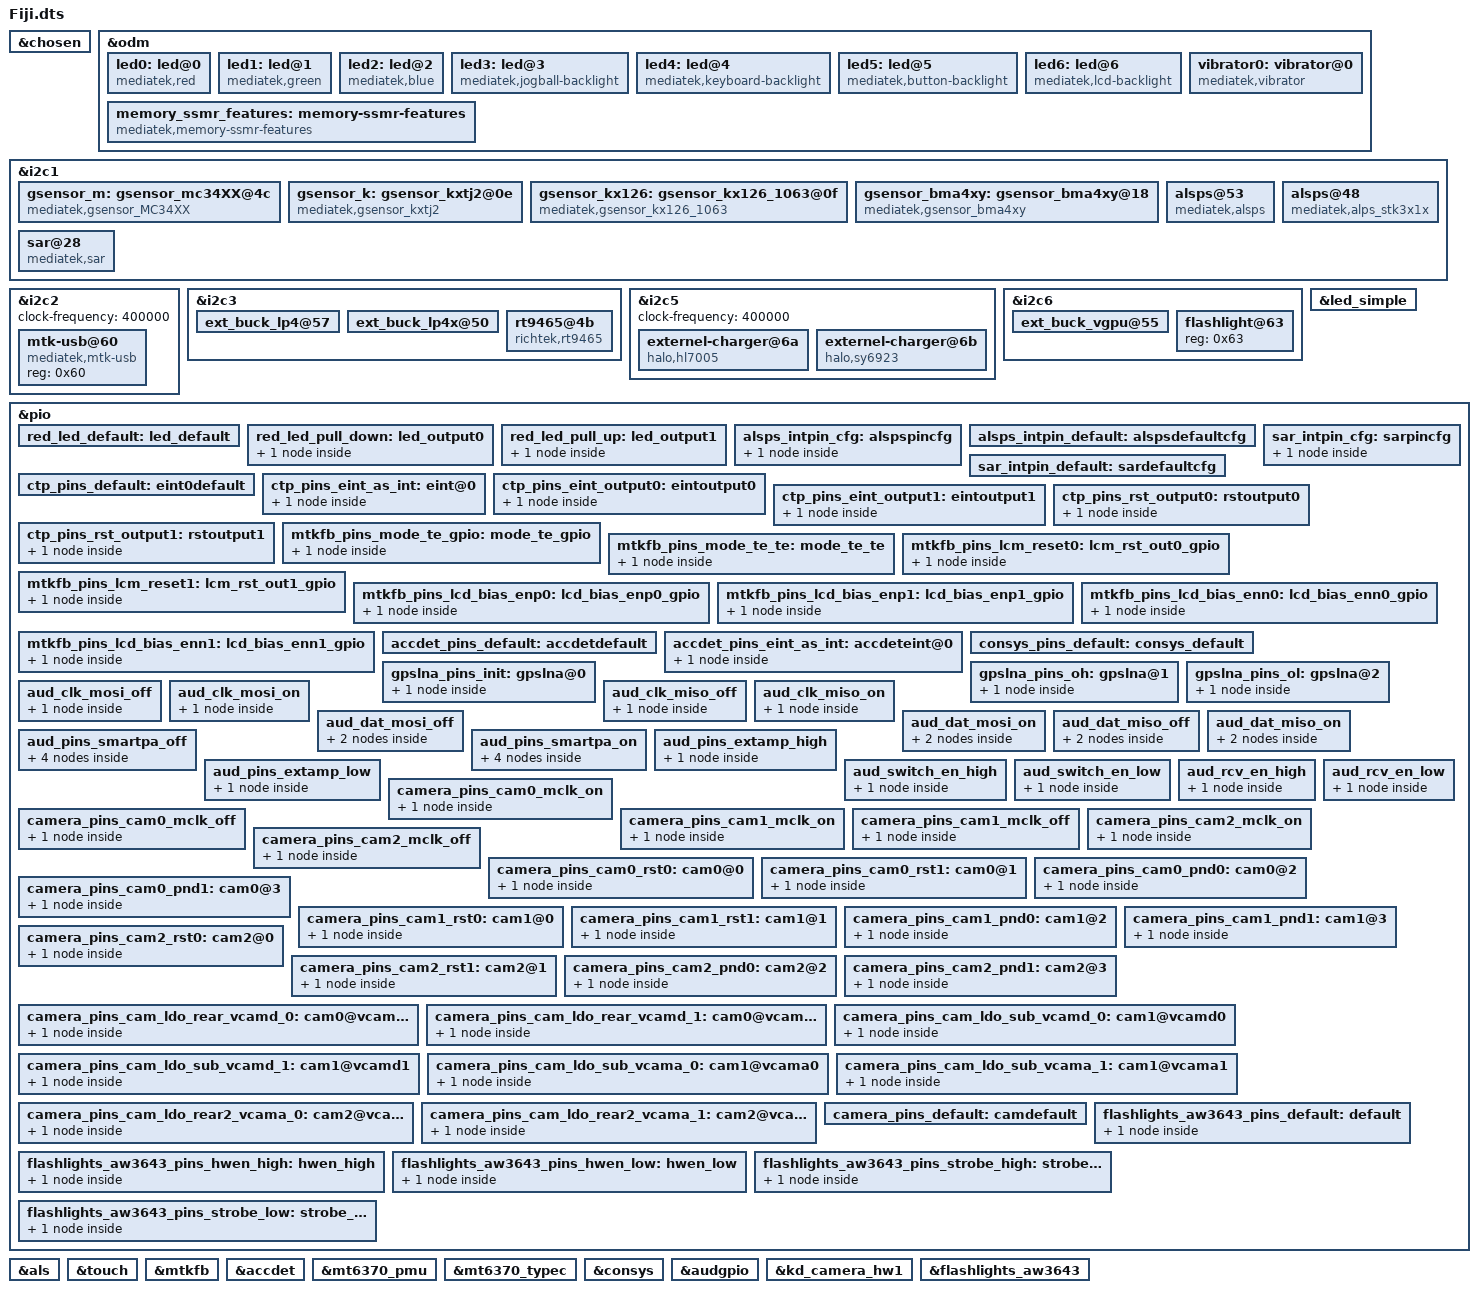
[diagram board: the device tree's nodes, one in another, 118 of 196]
#include <dt-bindings/interrupt-controller/arm-gic.h>
#include <dt-bindings/interrupt-controller/irq.h>
#include <dt-bindings/pinctrl/mt6761-pinfunc.h>
#include <dt-bindings/mmc/mt6761-msdc.h>
#include <dt-bindings/clock/mt6761-clk.h>

/dts-v1/;
/plugin/;

/* chosen */
&chosen {

	/* fpga may has no lk, we need to specify display info here */
	/* fb buffer is reserved using this dts by memory node above */
	atag,videolfb-fb_base_h = <0x0>;
	atag,videolfb-fb_base_l = <0x5e605000>;
	atag,videolfb-islcmfound = <1>;
	/* because no lk, so lcm is not inited */
	atag,videolfb-islcm_inited = <0>;
	atag,videolfb-fps= <6000>;
	atag,videolfb-vramSize= <0x017bb000>;
	atag,videolfb-lcmname= "nt35521_hd_dsi_vdo_truly_rt5081_drv";
};

&odm {
	led0:led@0 {
		compatible = "mediatek,red";
		led_mode = <3>;
		data = <1>;
		pwm_config = <0 0 0 0 0>;
	};
	led1:led@1 {
		compatible = "mediatek,green";
		led_mode = <3>;
		data = <2>;
		pwm_config = <0 0 0 0 0>;
	};
	led2:led@2 {
		compatible = "mediatek,blue";
		led_mode = <0>;
		data = <1>;
		pwm_config = <0 0 0 0 0>;
	};
	led3:led@3 {
		compatible = "mediatek,jogball-backlight";
		led_mode = <0>;
		data = <1>;
		pwm_config = <0 0 0 0 0>;
	};
	led4:led@4 {
		compatible = "mediatek,keyboard-backlight";
		led_mode = <0>;
		data = <1>;
		pwm_config = <0 0 0 0 0>;
	};
	led5:led@5 {
		compatible = "mediatek,button-backlight";
		led_mode = <0>;
		data = <1>;
		pwm_config = <0 0 0 0 0>;
	};
	led6:led@6 {
		compatible = "mediatek,lcd-backlight";
		led_mode = <4>;
		data = <1>;
		pwm_config = <0 2 0 0 0>;
	};
	vibrator0:vibrator@0 {
		compatible = "mediatek,vibrator";
		vib_timer = <25>;
		vib_limit = <9>;
		vib_vol= <0x0b>;
	};
	memory_ssmr_features: memory-ssmr-features {
		compatible = "mediatek,memory-ssmr-features";
		svp-size = <0 0>;
		iris-recognition-size = <0 0>;
		2d_fr-size = <0 0>;
		tui-size = <0 0>;
		wfd-size = <0 0>;
		prot-sharedmem-size = <0 0>;
	};
};

&i2c1 {
/*  start sensor */
	/*
	memsic@0 {
		compatible = “mediatek,mmc5603”;
		i2c_num = <1>;
		i2c_addr = <0x30 0 0 0>; 
		direction - <1>;
		is_batch_supported = <0>;
	}
	*/
	gsensor_m:gsensor_mc34XX@4c {
		compatible = "mediatek,gsensor_MC34XX";
		reg = <0x4c>;
		status = "okay";

		i2c_num	= <1>;
		i2c_addr = <0x4c 0 0 0>;
		direction = <2>;
		power_id = <0xffff>;
		power_vol = <0>;
		firlen = <16>;
		is_batch_supported = <1>;
	};

  	gsensor_k:gsensor_kxtj2@0e {
		compatible = "mediatek,gsensor_kxtj2";
		reg = <0x0e>;
		status = "okay";
		
		i2c_num	= <1>;
		i2c_addr = <0x0e 0 0 0>;
		direction = <6>;
		power_id = <0xffff>;
		power_vol = <0>;
		firlen = <16>;
		is_batch_supported = <1>;
	};
	gsensor_kx126:gsensor_kx126_1063@0f {
		compatible = "mediatek,gsensor_kx126_1063";
		reg = <0x0f>;
		status = "okay";
		
		i2c_num	= <1>;
		i2c_addr = <0x0f 0 0 0>;
		direction = <6>;
		power_id = <0xffff>;
		power_vol = <0>;
		firlen = <16>;
		is_batch_supported = <1>;
	};
	gsensor_bma4xy:gsensor_bma4xy@18 {
		compatible = "mediatek,gsensor_bma4xy";
		reg = <0x18>;
		status = "okay";
		
		i2c_num	= <1>;
		i2c_addr = <0x18 0 0 0>;
		direction = <6>;
		power_id = <0xffff>;
		power_vol = <0>;
		firlen = <16>;
		is_batch_supported = <1>;
	}; 

	alsps@53 {
		compatible = "mediatek,alsps";

		pinctrl-names = "pin_default", "pin_cfg";
		pinctrl-0 = <&alsps_intpin_default>;
		pinctrl-1 = <&alsps_intpin_cfg>;

		i2c_num = <1>;
		i2c_addr= <0x53 0 0 0>;
		polling_mode_ps = <0>;
		polling_mode_als = <1>;
		power_id = <0xffff>;
		power_vol = <0>;
		als_level = <
			0  133  304  502   1004  2005  3058 4000
			0  133  304   502  1004  2005  3058 4000
			0  133  304   502  1004  2005  3058 4000
			0  133  304  502   1004  2005  3058 4000
			0  133  304   502  1004  2005  3058 4000
			0  133  304   502  1004  2005  3058 4000
			>;
		als_value = < 0  133  304  502   1004  2005  3058   4000 >;
		ps_threshold_high               =  <700>;
		ps_threshold_low                =  <600>;
		is_batch_supported_ps = <0>;
		is_batch_supported_als = <0>;

	};

	alsps@48 {
		compatible = "mediatek,alps_stk3x1x";
		reg = <0x48>;
		status = "okay";

		pinctrl-names = "pin_default", "pin_cfg";
		pinctrl-0 = <&alsps_intpin_default>;
		pinctrl-1 = <&alsps_intpin_cfg>;

		interrupt-parent = <&pio>;
		interrupts = <1 IRQ_TYPE_LEVEL_LOW 1 0>;

		i2c_num				= <1>;
		i2c_addr				= <0x48 0 0 0>;
		polling_mode_ps			= <0>;
		polling_mode_als		= <1>;
		power_id				= <0xffff>;
		power_vol				= <0>;
		als_level = < 
					0  39   91    150    290    505     736    943
					0  82   174   299    582    1319    2940  3333
					0  123   264   399    627    1444   2144   2800
					0  63   144    237    445    724     991    1231
					0  72   163   258    560    1576   2400   3152
					0  112   240   475    746    1719   2552   3333
					  >;
		als_value = < 0  133  304  502   1004  2005  3058   4000 >;
		state_val		=  <0>;
		psctrl_val		=  <0x31>;
		alsctrl_val	= <0x38>;
		ledctrl_val	= <0xFF>;
		wait_val		= <0xF>;
		ps_threshold_high		=  <1700>;
		ps_threshold_low		=  <1500>;
		is_batch_supported_ps	= <0>;
		is_batch_supported_als	= <0>;
		//
                als_calib_enable = <1>;
                als_ch0_expect               =  <1000>;
                als_ch1_expect                =  <800>;
               // 
	};  

	sar@28 {
		compatible = "mediatek,sar";
		reg = <0x28>;

		pinctrl-names = "pin_default", "pin_cfg";
        pinctrl-0 = <&sar_intpin_default>;
        pinctrl-1 = <&sar_intpin_cfg>;

		Semtech,reg-num = <46>; /* total registers number to initialize*/
        Semtech,reg-init  = /bits/ 8 < 0x10 0x16
                                0x20 0x00
                                0x23 0x00
                                0x24 0x44
                                0x26 0x01
                                0x27 0x44
                                0x28 0x01 /*PH0 to CS0 input*/
                                0x29 0x10
                                0x2A 0x19 /*PH2 CS2-input,CS1-dync,CS0-HZ*/
                                0x2B 0x00
                                0x2C 0x12
                                0x2D 0x08
                                0x30 0x09
                                0x31 0x09
                                0x32 0x08
                                0x33 0x20
                                0x34 0x0C
                                0x35 0x00
                                0x36 0x1B
                                0x37 0x1B
                                0x40 0x00
                                0x41 0x00
                                0x42 0x00
                                0x43 0x00
                                0x44 0x00
                                0x45 0x05
                                0x46 0x00
                                0x47 0x00
                                0x48 0x00
                                0x49 0x80
                                0x4A 0x00
                                0x4B 0x00
                                0x4C 0x00
                                0x4D 0x00
                                0x4E 0x80
                                0x4F 0x0C
                                0x50 0x00
                                0x51 0x70
                                0x52 0x20
                                0x53 0xE1
                                0x54 0xF0
                                0x05 0x70
                                0x06 0x00
                                0x07 0x00
                                0x08 0x00
								0x11 0x24>;

	};

/* end sensor */
};
&i2c2 {
	#address-cells = <1>;
	#size-cells = <0>;
	clock-frequency = <400000>;

	mtk-usb@60 {
		compatible = "mediatek,mtk-usb";
		reg = <0x60>;
		status = "okay";
	};
};

&i2c3 {
	ext_buck_lp4@57 {
		regulator-name ="ext_buck_vdd2";
		regulator-min-microvolt = <300000>;
		regulator-max-microvolt = <1300000>;
		vsel_pin = <0>;
	};

	ext_buck_lp4x@50 {
		regulator-name ="ext_buck_vddq";
		regulator-min-microvolt = <300000>;
		regulator-max-microvolt = <1300000>;
		vsel_pin = <1>;
	};
};
&i2c5 {
	#address-cells = <1>;
	#size-cells = <0>;
	clock-frequency = <400000>;

	externel-charger@6a{
		compatible = "halo,hl7005";
		reg = <0x6a>;
		status = "okay";
		ichg = <1050000>; /* uA */
	};
	externel-charger@6b{
		compatible = "halo,sy6923";
		reg = <0x6b>;
		status = "okay";
		ichg = <1050000>; /* uA */
	};
};
&i2c6 {
	ext_buck_vgpu@55 {
		regulator-name ="ext_buck_vgpu";
		regulator-min-microvolt = <300000>;
		regulator-max-microvolt = <1300000>;
		vsel_pin = <2>;
	};
	flashlight@63 {
		reg = <0x63>;
		status = "okay";
	};
};
&led_simple {
	pinctrl-names = "default", "red_led_output0", "red_led_output1";
	pinctrl-0 = <&red_led_default>;
	pinctrl-1 = <&red_led_pull_down>;
	pinctrl-2 = <&red_led_pull_up>;
	status = "okay";
};
&pio {
	red_led_default: led_default {
	};
	red_led_pull_down: led_output0 {
		pins_cmd_dat {
			pinmux = <PINMUX_GPIO159__FUNC_GPIO159>;
			slew-rate = <1>;
			output-low;
		};
	};
	red_led_pull_up: led_output1 {
		pins_cmd_dat {
			pinmux = <PINMUX_GPIO159__FUNC_GPIO159>;
			slew-rate = <1>;
			output-high;
		};
	};
};

&als {
		pinctrl-names = "pin_default", "pin_cfg";
		pinctrl-0 = <&alsps_intpin_default>;
		pinctrl-1 = <&alsps_intpin_cfg>;
};

&pio {
	alsps_intpin_cfg: alspspincfg {

		pins_cmd_dat {
			pinmux = <PINMUX_GPIO6__FUNC_GPIO6>;
			slew-rate = <0>;
			bias-pull-up = <MTK_PUPD_SET_R1R0_01>;
		};
	};

	alsps_intpin_default: alspsdefaultcfg {

	};
};

&pio {
	sar_intpin_cfg: sarpincfg {

		pins_cmd_dat {
			pins = <PINMUX_GPIO2__FUNC_GPIO2>;
			slew-rate = <0>;
			bias-pull-up = <MTK_PUPD_SET_R1R0_01>;
		};
	};

	sar_intpin_default: sardefaultcfg {

	};
};

/* TOUCH start */
&touch {
	tpd-resolution = <720 1280>;
	use-tpd-button = <0>;
	tpd-key-num = <3>;
	tpd-key-local= <139 172 158 0>;
	tpd-key-dim-local = <90 883 100 40 230
				 883 100 40 370 883 100 40 0 0 0 0>;
	tpd-max-touch-num = <5>;
	tpd-filter-enable = <1>;
	tpd-filter-pixel-density = <106>;
	tpd-filter-custom-prameters = <0 0 0 0 0 0 0 0 0 0 0 0>;
	tpd-filter-custom-speed = <0 0 0>;
	pinctrl-names = "default", "state_eint_as_int", "state_eint_output0",
		"state_eint_output1", "state_rst_output0", "state_rst_output1";
	pinctrl-0 = <&ctp_pins_default>;
	pinctrl-1 = <&ctp_pins_eint_as_int>;
	pinctrl-2 = <&ctp_pins_eint_output0>;
	pinctrl-3 = <&ctp_pins_eint_output1>;
	pinctrl-4 = <&ctp_pins_rst_output0>;
	pinctrl-5 = <&ctp_pins_rst_output1>;
	status = "okay";
};
&pio {
	ctp_pins_default: eint0default {
	};
	ctp_pins_eint_as_int: eint@0 {
		pins_cmd_dat {
			pinmux = <PINMUX_GPIO0__FUNC_GPIO0>;
			slew-rate = <0>;
			bias-disable;
		};
	};
	ctp_pins_eint_output0: eintoutput0 {
		pins_cmd_dat {
			pinmux = <PINMUX_GPIO0__FUNC_GPIO0>;
			slew-rate = <1>;
			output-low;
		};
	};
	ctp_pins_eint_output1: eintoutput1 {
		pins_cmd_dat {
			pinmux = <PINMUX_GPIO0__FUNC_GPIO0>;
			slew-rate = <1>;
			output-high;
		};
	};
	ctp_pins_rst_output0: rstoutput0 {
		pins_cmd_dat {
			pinmux = <PINMUX_GPIO174__FUNC_GPIO174>;
			slew-rate = <1>;
			output-low;
		};
	};
	ctp_pins_rst_output1: rstoutput1 {
		pins_cmd_dat {
			pinmux = <PINMUX_GPIO174__FUNC_GPIO174>;
			slew-rate = <1>;
			output-high;
		};
	};
};
/* TOUCH end */
/* DISPSYS GPIO standardization */
&pio {
	mtkfb_pins_mode_te_gpio: mode_te_gpio {
		pins_cmd_dat {
			pinmux = <PINMUX_GPIO44__FUNC_DSI_TE>;
		};
	};

	mtkfb_pins_mode_te_te: mode_te_te {
		pins_cmd_dat {
			pinmux = <PINMUX_GPIO44__FUNC_DSI_TE>;
		};
	};

	mtkfb_pins_lcm_reset0: lcm_rst_out0_gpio {
		pins_cmd_dat {
			pinmux = <PINMUX_GPIO45__FUNC_GPIO45>;
			slew-rate = <1>;
			output-low;
		};
	};

	mtkfb_pins_lcm_reset1: lcm_rst_out1_gpio {
		pins_cmd_dat {
			pinmux = <PINMUX_GPIO45__FUNC_GPIO45>;
			slew-rate = <1>;
			output-high;
		};
	};

	mtkfb_pins_lcd_bias_enp0: lcd_bias_enp0_gpio {
		pins_cmd_dat {
			pinmux = <PINMUX_GPIO172__FUNC_GPIO172>;
			slew-rate = <1>;
			output-low;
		};
	};
	mtkfb_pins_lcd_bias_enp1: lcd_bias_enp1_gpio {
		pins_cmd_dat {
			pinmux = <PINMUX_GPIO172__FUNC_GPIO172>;
			slew-rate = <1>;
			output-high;
		};
	};

	mtkfb_pins_lcd_bias_enn0: lcd_bias_enn0_gpio {
		pins_cmd_dat {
			pinmux = <PINMUX_GPIO173__FUNC_GPIO173>;
			slew-rate = <1>;
			output-low;
		};
	};
	mtkfb_pins_lcd_bias_enn1: lcd_bias_enn1_gpio {
		pins_cmd_dat {
			pinmux = <PINMUX_GPIO173__FUNC_GPIO173>;
			slew-rate = <1>;
			output-high;
		};
	};

};

&mtkfb {
	pinctrl-names = "mode_te_gpio", "mode_te_te", "lcm_rst_out0_gpio",
		"lcm_rst_out1_gpio","lcd_bias_enp0_gpio", "lcd_bias_enp1_gpio", "lcd_bias_enn0_gpio", "lcd_bias_enn1_gpio";
	pinctrl-0 = <&mtkfb_pins_mode_te_gpio>;
	pinctrl-1 = <&mtkfb_pins_mode_te_te>;
	pinctrl-3 = <&mtkfb_pins_lcm_reset0>;
	pinctrl-4 = <&mtkfb_pins_lcm_reset1>;
	pinctrl-7 = <&mtkfb_pins_lcd_bias_enp0>;
	pinctrl-8 = <&mtkfb_pins_lcd_bias_enp1>;
	pinctrl-9 = <&mtkfb_pins_lcd_bias_enn0>;
	pinctrl-10 = <&mtkfb_pins_lcd_bias_enn1>;
	status = "okay";
};
/* DISPSYS GPIO standardization end */
&accdet {
	accdet-mic-vol = <6>;
	headset-mode-setting = <0x500 0x500 1 0x1f0 0x800 0x800 0x20 0x44>;
	accdet-plugout-debounce = <1>;
	accdet-mic-mode = <1>;
	headset-eint-level-pol = <8>;
	headset-three-key-threshold = <0 80 175 400>;
	headset-three-key-threshold-CDD = <0 121 192 600>;
	headset-four-key-threshold = <0 58 121 192 400>;
	pinctrl-names = "default", "state_eint_as_int";
	pinctrl-0 = <&accdet_pins_default>;
	pinctrl-1 = <&accdet_pins_eint_as_int>;
	status = "okay";
};
&pio {
	accdet_pins_default: accdetdefault {
	};
	accdet_pins_eint_as_int: accdeteint@0 {
		pins_cmd_dat {
			pinmux = <PINMUX_GPIO9__FUNC_GPIO9>;
			slew-rate = <0>;
			bias-disable;
		};
	};
};

&mt6370_pmu {
	mt6370,intr_gpio_num = <11>; /* direct defined GPIO num */
	mt6370,intr_gpio = <&pio 11 0x0>;
};
#if 0
&charger {
	algorithm_name = "DualSwitchCharging";
	chg1_ta_ac_charger_current = <2000000>;
	chg2_ta_ac_charger_current = <2000000>;
};
#endif
&i2c3 {
	rt9465@4b {
		compatible = "richtek,rt9465";
		reg = <0x4b>;
		status = "okay";
		rt,en_gpio_num = <176>;
		rt,en_gpio = <&pio 176 0x0>;
		rt,intr_gpio_num = <23>; /* direct defined GPIO num */
		rt,intr_gpio = <&pio 23 0x0>;
		interrupt-names = "wdtmri";
		charger_name = "secondary_chg";
		ichg = <1500000>; /* uA */
		mivr = <4500000>; /* uV */
		cv = <4550000>; /* uV */
		ieoc = <700000>; /* uA */
		safety_timer = <12>; /* hour */
		en_st; /* safety timer */
		/* en_te; */
		en_wdt;
	};
};

&mt6370_typec {
	mt6370pd,intr_gpio_num = <41>; /* direct defined GPIO num */
	mt6370pd,intr_gpio = <&pio 41 0x0>;
};
/* CONSYS GPIO standardization */
&pio {
	consys_pins_default: consys_default {
	};
	gpslna_pins_init: gpslna@0 {
		pins_cmd_dat {
			pinmux = <PINMUX_GPIO91__FUNC_GPIO91>;
			slew-rate = <0>;
			bias-disable;
			output-low;
		};
	};
	gpslna_pins_oh: gpslna@1 {
		pins_cmd_dat {
			pinmux = <PINMUX_GPIO91__FUNC_GPIO91>;
			slew-rate = <1>;
			output-high;
		};
	};
	gpslna_pins_ol: gpslna@2 {
		pins_cmd_dat {
			pinmux = <PINMUX_GPIO91__FUNC_GPIO91>;
			slew-rate = <1>;
			output-low;
		};
	};
};
&consys {
	pinctrl-names = "default", "gps_lna_state_init",
		"gps_lna_state_oh", "gps_lna_state_ol";
	pinctrl-0 = <&consys_pins_default>;
	pinctrl-1 = <&gpslna_pins_init>;
	pinctrl-2 = <&gpslna_pins_oh>;
	pinctrl-3 = <&gpslna_pins_ol>;
	status = "okay";
};
/* CONSYS end */

/* AUDIO GPIO standardization */
&audgpio {
	pinctrl-names = "aud_clk_mosi_off",
			"aud_clk_mosi_on",
			"aud_clk_miso_off",
			"aud_clk_miso_on",
			"aud_dat_mosi_off",
			"aud_dat_mosi_on",
			"aud_dat_miso_off",
			"aud_dat_miso_on",
			"aud_smartpa_off",
			"aud_smartpa_on",
			"extamp-pullhigh",
			"extamp-pulllow",
			"aud_switch_en_high",
			"aud_switch_en_low",
			"aud_rcv_en_high",
			"aud_rcv_en_low";
	pinctrl-0 = <&aud_clk_mosi_off>;
	pinctrl-1 = <&aud_clk_mosi_on>;
	pinctrl-2 = <&aud_clk_miso_off>;
	pinctrl-3 = <&aud_clk_miso_on>;
	pinctrl-4 = <&aud_dat_mosi_off>;
	pinctrl-5 = <&aud_dat_mosi_on>;
	pinctrl-6 = <&aud_dat_miso_off>;
	pinctrl-7 = <&aud_dat_miso_on>;
	pinctrl-8 = <&aud_pins_smartpa_off>;
	pinctrl-9 = <&aud_pins_smartpa_on>;
	pinctrl-10 = <&aud_pins_extamp_high>;
	pinctrl-11 = <&aud_pins_extamp_low>;
	pinctrl-12 = <&aud_switch_en_high>;
	pinctrl-13 = <&aud_switch_en_low>;
	pinctrl-14 = <&aud_rcv_en_high>;
	pinctrl-15 = <&aud_rcv_en_low>;
	status = "okay";
};

&pio {
	aud_clk_mosi_off: aud_clk_mosi_off {
		pins_cmd0_dat {
			pinmux = <PINMUX_GPIO136__FUNC_GPIO136>;
		};
	};

	aud_clk_mosi_on: aud_clk_mosi_on {
		pins_cmd0_dat {
			pinmux = <PINMUX_GPIO136__FUNC_AUD_CLK_MOSI>;
		};
	};

	aud_clk_miso_off: aud_clk_miso_off {
		pins_cmd0_dat {
			pinmux = <PINMUX_GPIO140__FUNC_GPIO140>;
		};
	};

	aud_clk_miso_on: aud_clk_miso_on {
		pins_cmd0_dat {
			pinmux = <PINMUX_GPIO140__FUNC_AUD_CLK_MISO>;
		};
	};

	aud_dat_mosi_off: aud_dat_mosi_off {
		pins_cmd1_dat {
			pinmux = <PINMUX_GPIO138__FUNC_GPIO138>;
			input-enable;
			slew-rate = <0>;
			bias-disable;
		};
		pins_cmd2_dat {
			pinmux = <PINMUX_GPIO139__FUNC_GPIO139>;
			input-enable;
			slew-rate = <0>;
			bias-disable;
		};
	};

	aud_dat_mosi_on: aud_dat_mosi_on {
		pins_cmd1_dat {
			pinmux = <PINMUX_GPIO138__FUNC_AUD_DAT_MOSI0>;
		};
		pins_cmd2_dat {
			pinmux = <PINMUX_GPIO139__FUNC_AUD_DAT_MOSI1>;
		};
	};

	aud_dat_miso_off: aud_dat_miso_off {
		pins_cmd1_dat {
			pinmux = <PINMUX_GPIO142__FUNC_GPIO142>;
			input-enable;
			slew-rate = <0>;
			bias-disable;
		};
		pins_cmd2_dat {
			pinmux = <PINMUX_GPIO143__FUNC_GPIO143>;
			input-enable;
			slew-rate = <0>;
			bias-disable;
		};
	};

	aud_dat_miso_on: aud_dat_miso_on {
		pins_cmd1_dat {
			pinmux = <PINMUX_GPIO142__FUNC_AUD_DAT_MISO0>;
		};
		pins_cmd2_dat {
			pinmux = <PINMUX_GPIO143__FUNC_AUD_DAT_MISO1>;
		};
	};

	aud_pins_smartpa_off: aud_pins_smartpa_off {
		pins_cmd0_dat {
			pinmux = <PINMUX_GPIO17__FUNC_GPIO17>;
		};
		pins_cmd1_dat {
			pinmux = <PINMUX_GPIO18__FUNC_GPIO18>;
		};
		pins_cmd2_dat {
			pinmux = <PINMUX_GPIO19__FUNC_GPIO19>;
		};
		pins_cmd3_dat {
			pinmux = <PINMUX_GPIO20__FUNC_GPIO20>;
		};
	};

	aud_pins_smartpa_on: aud_pins_smartpa_on {
		pins_cmd0_dat {
			pinmux = <PINMUX_GPIO17__FUNC_I2S0_DI>;
		};
		pins_cmd1_dat {
			pinmux = <PINMUX_GPIO18__FUNC_I2S3_BCK>;
		};
		pins_cmd2_dat {
			pinmux = <PINMUX_GPIO19__FUNC_I2S3_LRCK>;
		};
		pins_cmd3_dat {
			pinmux = <PINMUX_GPIO20__FUNC_I2S3_DO>;
		};
	};
	aud_pins_extamp_high: aud_pins_extamp_high {
		pins_cmd_dat {
			pinmux = <PINMUX_GPIO153__FUNC_GPIO153>;
			slew-rate = <1>;
			output-high;
		};
	};

	aud_pins_extamp_low: aud_pins_extamp_low {
		pins_cmd_dat {
			pinmux = <PINMUX_GPIO153__FUNC_GPIO153>;
			slew-rate = <1>;
			output-low;
		};
	};

	aud_switch_en_high: aud_switch_en_high {
		pins_cmd_dat {
			pinmux = <PINMUX_GPIO170__FUNC_GPIO170>;
			slew-rate = <1>;
			output-high;
		};
	};

	aud_switch_en_low: aud_switch_en_low {
		pins_cmd_dat {
			pinmux = <PINMUX_GPIO170__FUNC_GPIO170>;
			slew-rate = <1>;
			output-low;
		};
	};

	aud_rcv_en_high: aud_rcv_en_high {
		pins_cmd_dat {
			pinmux = <PINMUX_GPIO171__FUNC_GPIO171>;
			slew-rate = <1>;
			output-high;
		};
	};

	aud_rcv_en_low: aud_rcv_en_low {
		pins_cmd_dat {
			pinmux = <PINMUX_GPIO171__FUNC_GPIO171>;
			slew-rate = <1>;
			output-low;
		};
	};
};
/* AUDIO end */

&pio {
	camera_pins_cam0_mclk_on: camera_pins_cam0_mclk_on {
		pins_cmd_dat {
			pinmux = <PINMUX_GPIO99__FUNC_CMMCLK0>;
		};
	};
	camera_pins_cam0_mclk_off: camera_pins_cam0_mclk_off {
		pins_cmd_dat {
			pinmux = <PINMUX_GPIO99__FUNC_GPIO99>;
		};
	};
	camera_pins_cam1_mclk_on: camera_pins_cam1_mclk_on {
		pins_cmd_dat {
			pinmux = <PINMUX_GPIO99__FUNC_CMMCLK0>;
		};
	};
	camera_pins_cam1_mclk_off: camera_pins_cam1_mclk_off {
		pins_cmd_dat {
			pinmux = <PINMUX_GPIO99__FUNC_GPIO99>;
		};
	};
	camera_pins_cam2_mclk_on: camera_pins_cam2_mclk_on {
		pins_cmd_dat {
			pinmux = <PINMUX_GPIO108__FUNC_CMMCLK2>;
		};
	};
	camera_pins_cam2_mclk_off: camera_pins_cam2_mclk_off {
		pins_cmd_dat {
			pinmux = <PINMUX_GPIO108__FUNC_GPIO108>;
		};
	};
	camera_pins_cam0_rst0: cam0@0 {
		pins_cmd_dat {
			pinmux = <PINMUX_GPIO101__FUNC_GPIO101>;
			slew-rate = <1>;
			output-low;
		};
	};
	camera_pins_cam0_rst1: cam0@1 {
		pins_cmd_dat {
			pinmux = <PINMUX_GPIO101__FUNC_GPIO101>;
			slew-rate = <1>;
			output-high;
		};
	};
	camera_pins_cam0_pnd0: cam0@2 {
		pins_cmd_dat {
			pinmux = <PINMUX_GPIO97__FUNC_GPIO97>;
			slew-rate = <1>;
			output-low;
		};
	};
	camera_pins_cam0_pnd1: cam0@3 {
		pins_cmd_dat {
			pinmux = <PINMUX_GPIO97__FUNC_GPIO97>;
			slew-rate = <1>;
			output-high;
		};
	};
	camera_pins_cam1_rst0: cam1@0 {
		pins_cmd_dat {
			pinmux = <PINMUX_GPIO102__FUNC_GPIO102>;
			slew-rate = <1>;
			output-low;
		};
	};
	camera_pins_cam1_rst1: cam1@1 {
		pins_cmd_dat {
			pinmux = <PINMUX_GPIO102__FUNC_GPIO102>;
			slew-rate = <1>;
			output-high;
		};
	};
	camera_pins_cam1_pnd0: cam1@2 {
		pins_cmd_dat {
			pinmux = <PINMUX_GPIO98__FUNC_GPIO98>;
			slew-rate = <1>;
			output-low;
		};
	};
	camera_pins_cam1_pnd1: cam1@3 {
		pins_cmd_dat {
			pinmux = <PINMUX_GPIO98__FUNC_GPIO98>;
			slew-rate = <1>;
			output-high;
		};
	};
	camera_pins_cam2_rst0: cam2@0 {
		pins_cmd_dat {
			pinmux = <PINMUX_GPIO87__FUNC_GPIO87>;
			slew-rate = <1>;
			output-low;
		};
	};
	camera_pins_cam2_rst1: cam2@1 {
		pins_cmd_dat {
			pinmux = <PINMUX_GPIO87__FUNC_GPIO87>;
			slew-rate = <1>;
			output-high;
		};
	};
	camera_pins_cam2_pnd0: cam2@2 {
		pins_cmd_dat {
			pinmux = <PINMUX_GPIO160__FUNC_GPIO160>;
			slew-rate = <1>;
			output-low;
		};
	};
	camera_pins_cam2_pnd1: cam2@3 {
		pins_cmd_dat {
			pinmux = <PINMUX_GPIO160__FUNC_GPIO160>;
			slew-rate = <1>;
			output-high;
		};
	};
	camera_pins_cam_ldo_rear_vcamd_0: cam0@vcamd0 {
		pins_cmd_dat {
			pinmux = <PINMUX_GPIO88__FUNC_GPIO88>;
			slew-rate = <1>;
			output-low;
		};
	};
	camera_pins_cam_ldo_rear_vcamd_1: cam0@vcamd1 {
		pins_cmd_dat {
			pinmux = <PINMUX_GPIO88__FUNC_GPIO88>;
			slew-rate = <1>;
			output-high;
		};
	};
	camera_pins_cam_ldo_sub_vcamd_0: cam1@vcamd0 {
		pins_cmd_dat {
			pinmux = <PINMUX_GPIO170__FUNC_GPIO170>;
			slew-rate = <1>;
			output-low;
		};
	};
	camera_pins_cam_ldo_sub_vcamd_1: cam1@vcamd1 {
		pins_cmd_dat {
			pinmux = <PINMUX_GPIO170__FUNC_GPIO170>;
			slew-rate = <1>;
			output-high;
		};
	};
	camera_pins_cam_ldo_sub_vcama_0: cam1@vcama0 {
		pins_cmd_dat {
			pinmux = <PINMUX_GPIO169__FUNC_GPIO169>;
			slew-rate = <1>;
			output-low;
		};
	};
	camera_pins_cam_ldo_sub_vcama_1: cam1@vcama1 {
		pins_cmd_dat {
			pinmux = <PINMUX_GPIO169__FUNC_GPIO169>;
			slew-rate = <1>;
			output-high;
		};
	};
	camera_pins_cam_ldo_rear2_vcama_0: cam2@vcama0 {
		pins_cmd_dat {
			pinmux = <PINMUX_GPIO159__FUNC_GPIO159>;
			slew-rate = <1>;
			output-low;
		};
	};
	camera_pins_cam_ldo_rear2_vcama_1: cam2@vcama1 {
		pins_cmd_dat {
			pinmux = <PINMUX_GPIO159__FUNC_GPIO159>;
			slew-rate = <1>;
			output-high;
		};
	};
	camera_pins_default: camdefault {
	};

};

&kd_camera_hw1 {
	pinctrl-names = "default",
			"cam0_rst0",
			"cam0_rst1",
			"cam0_pnd0",
			"cam0_pnd1",
			"cam1_rst0",
			"cam1_rst1",
			"cam1_pnd0",
			"cam1_pnd1",
			"cam2_rst0",
			"cam2_rst1",
			"cam2_pnd0",
			"cam2_pnd1",
			"cam0_vcamd_on",
			"cam0_vcamd_off",
			"cam1_vcamd_on",
			"cam1_vcamd_off",
			"cam1_vcama_on",
			"cam1_vcama_off",
			"cam2_vcama_on",
			"cam2_vcama_off",
			"cam0_mclk_on",
			"cam0_mclk_off",
			"cam1_mclk_on",
			"cam1_mclk_off",
			"cam2_mclk_on",
			"cam2_mclk_off";

	pinctrl-0 = <&camera_pins_default>;
	pinctrl-1 = <&camera_pins_cam0_rst0>;
	pinctrl-2 = <&camera_pins_cam0_rst1>;
	pinctrl-3 = <&camera_pins_cam0_pnd0>;
	pinctrl-4 = <&camera_pins_cam0_pnd1>;
	pinctrl-5 = <&camera_pins_cam1_rst0>;
	pinctrl-6 = <&camera_pins_cam1_rst1>;
	pinctrl-7 = <&camera_pins_cam1_pnd0>;
	pinctrl-8 = <&camera_pins_cam1_pnd1>;
	pinctrl-9 = <&camera_pins_cam2_rst0>;
	pinctrl-10 = <&camera_pins_cam2_rst1>;
	pinctrl-11 = <&camera_pins_cam2_pnd0>;
	pinctrl-12 = <&camera_pins_cam2_pnd1>;
	pinctrl-13 = <&camera_pins_cam_ldo_rear_vcamd_1>;
	pinctrl-14 = <&camera_pins_cam_ldo_rear_vcamd_0>;
	pinctrl-15 = <&camera_pins_cam_ldo_sub_vcamd_1>;
	pinctrl-16 = <&camera_pins_cam_ldo_sub_vcamd_0>;
	pinctrl-17 = <&camera_pins_cam_ldo_sub_vcama_1>;
	pinctrl-18 = <&camera_pins_cam_ldo_sub_vcama_0>;
	pinctrl-19 = <&camera_pins_cam_ldo_rear2_vcama_1>;
	pinctrl-20 = <&camera_pins_cam_ldo_rear2_vcama_0>;
	pinctrl-21 = <&camera_pins_cam0_mclk_on>;
	pinctrl-22 = <&camera_pins_cam0_mclk_off>;
	pinctrl-23 = <&camera_pins_cam1_mclk_on>;
	pinctrl-24 = <&camera_pins_cam1_mclk_off>;
	pinctrl-25 = <&camera_pins_cam2_mclk_on>;
	pinctrl-26 = <&camera_pins_cam2_mclk_off>;
	status = "okay";

};

/* flashlight begin */

&pio{
    	flashlights_aw3643_pins_default: default {
		pins_cmd_dat {
			pinmux = <PINMUX_GPIO151__FUNC_GPIO151>;
			slew-rate = <1>;
			output-high;
		};
	};
	flashlights_aw3643_pins_hwen_high: hwen_high {
		pins_cmd_dat {
			pinmux = <PINMUX_GPIO151__FUNC_GPIO151>;
			slew-rate = <1>;
			output-high;
		};
	};
	flashlights_aw3643_pins_hwen_low: hwen_low {
		pins_cmd_dat {
			pinmux = <PINMUX_GPIO151__FUNC_GPIO151>;
			slew-rate = <1>;
			output-low;
		};
	};
	flashlights_aw3643_pins_strobe_high: strobe_high {
		pins_cmd_dat {
			pinmux = <PINMUX_GPIO150__FUNC_GPIO150>;
			slew-rate = <1>;
			output-high;
		};
	};
	flashlights_aw3643_pins_strobe_low: strobe_low {
		pins_cmd_dat {
			pinmux = <PINMUX_GPIO150__FUNC_GPIO150>;
			slew-rate = <1>;
			output-low;
		};
	};

};

&flashlights_aw3643{
    pinctrl-names = "default",
			"hwen_high",
			"hwen_low",
			"strobe_high",
			"strobe_low";

    	pinctrl-0 = <&flashlights_aw3643_pins_default>;
	pinctrl-1 = <&flashlights_aw3643_pins_hwen_high>;
	pinctrl-2 = <&flashlights_aw3643_pins_hwen_low>;
	pinctrl-3 = <&flashlights_aw3643_pins_strobe_high>;
	pinctrl-4 = <&flashlights_aw3643_pins_strobe_low>;
    status = "okay";
};

/* flashlight end */

#include "bat_setting/mt6761_battery_table_fiji.dtsi"

#include <Fiji/cust.dtsi>
/*End of this file, DO NOT ADD ANYTHING HERE*/
